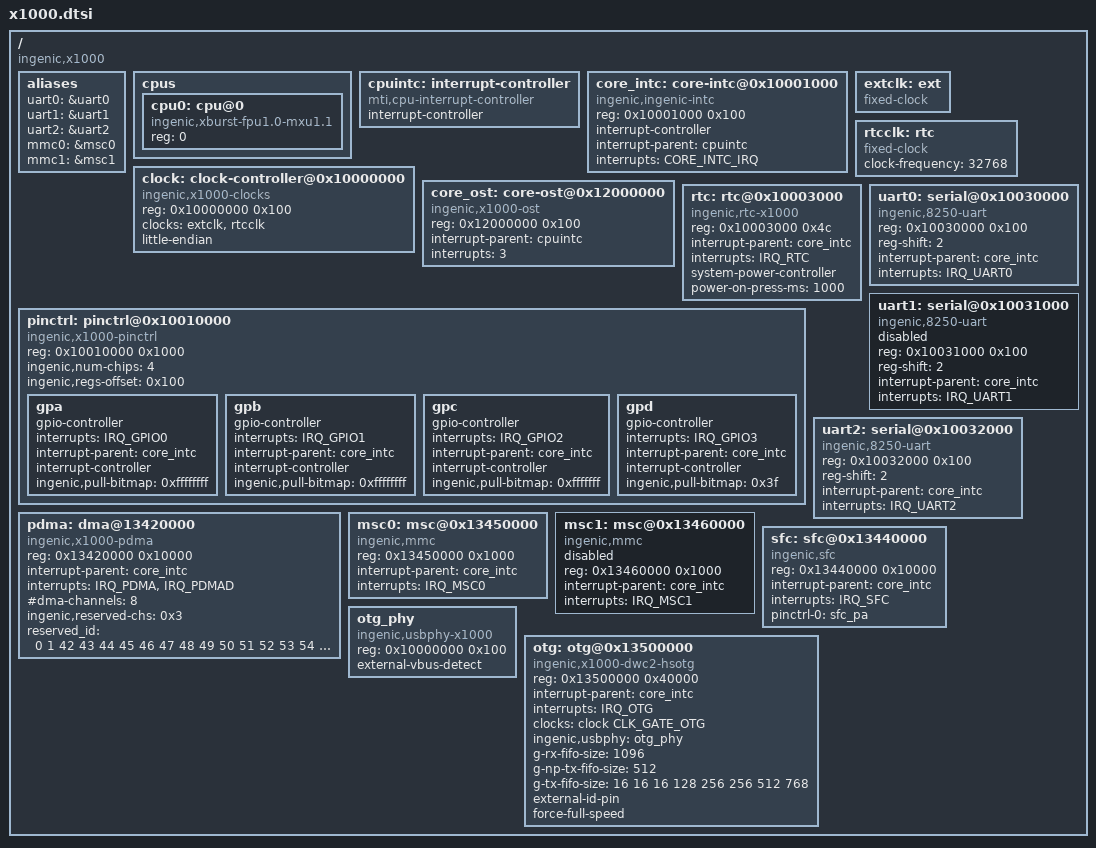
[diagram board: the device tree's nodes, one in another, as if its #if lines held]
// SPDX-License-Identifier: GPL-2.0
#include <dt-bindings/interrupt-controller/x1000-irq.h>
#include <dt-bindings/clock/ingenic,tcu.h>
#include <dt-bindings/clock/x1000-cgu.h>
#include <dt-bindings/clock/ingenic-x1000.h>
#include <dt-bindings/dma/x1000-dma.h>

/ {
	#address-cells = <1>;
	#size-cells = <1>;
	compatible = "ingenic,x1000", "ingenic,x1000e";

	aliases: aliases {
		uart0 = &uart0;
		uart1 = &uart1;
		uart2 = &uart2;
		mmc0 = &msc0;
		mmc1 = &msc1;
	};

	cpus {
		#address-cells = <1>;
		#size-cells = <0>;

		cpu0: cpu@0 {
			device_type = "cpu";
			compatible = "ingenic,xburst-fpu1.0-mxu1.1";
			reg = <0>;

			clock-names = "cpu";
		};
	};

	cpuintc: interrupt-controller {
		#address-cells = <0>;
		#interrupt-cells = <1>;
		interrupt-controller;
		compatible = "mti,cpu-interrupt-controller";
	};

	core_intc: core-intc@0x10001000 {
		compatible = "ingenic,ingenic-intc";
		reg = <0x10001000 0x100>;
		interrupt-controller;
		#interrupt-cells = <1>;
		interrupt-parent = <&cpuintc>;
		interrupts = <CORE_INTC_IRQ>;
		interrupt-names ="intc";
	};

	extclk: ext {
		compatible = "fixed-clock";
		#clock-cells = <0>;
	};

	rtcclk: rtc {
		compatible = "fixed-clock";
		#clock-cells = <0>;
		clock-frequency = <32768>;
	};

	clock: clock-controller@0x10000000 {
		compatible = "ingenic,x1000-clocks", "syscon";
		reg = <0x10000000 0x100>;
		clocks = <&extclk>, <&rtcclk>;
		clock-names = "ext", "rtc_ext";
		#clock-cells = <1>;
		little-endian;
	};


	core_ost: core-ost@0x12000000 {
		compatible = "ingenic,x1000-ost";
		reg = <0x12000000 0x100>;
		interrupt-parent = <&cpuintc>;
		interrupt-names = "sys_ost";
		interrupts = <3>;
	};

	rtc: rtc@0x10003000 {
		compatible = "ingenic,rtc-x1000";
		reg = <0x10003000 0x4c>;
		interrupt-parent = <&core_intc>;
		interrupts = <IRQ_RTC>;
		system-power-controller;
		power-on-press-ms = <1000>;
	};


	pinctrl: pinctrl@0x10010000 {
		compatible = "ingenic,x1000-pinctrl";
		reg = <0x10010000 0x1000>;
		ingenic,num-chips = <4>;
		ingenic,regs-offset = <0x100>;

		gpa: gpa {
			gpio-controller;
			#gpio-cells = <3>;
			#ingenic,pincfg-cells = <3>;
			#ingenic,pinmux-cells = <2>;
			interrupts = <IRQ_GPIO0>;
			interrupt-parent = <&core_intc>;
			interrupt-controller;
			#interrupt-cells = <3>;
			ingenic,pull-bitmap = <0xffffffff>;
		};

		gpb: gpb {
			gpio-controller;
			#gpio-cells = <3>;
			#ingenic,pincfg-cells = <3>;
			#ingenic,pinmux-cells = <2>;
			interrupts = <IRQ_GPIO1>;
			interrupt-parent = <&core_intc>;
			interrupt-controller;
			#interrupt-cells = <3>;
			ingenic,pull-bitmap = <0xffffffff>;
		};

		gpc: gpc {
			gpio-controller;
			#gpio-cells = <3>;
			#ingenic,pincfg-cells = <3>;
			#ingenic,pinmux-cells = <2>;
			interrupts = <IRQ_GPIO2>;
			interrupt-parent = <&core_intc>;
			interrupt-controller;
			#interrupt-cells = <3>;
			ingenic,pull-bitmap = <0xfffffff>;
		};

		gpd: gpd {
			gpio-controller;
			#gpio-cells = <3>;
			#ingenic,pincfg-cells = <3>;
			#ingenic,pinmux-cells = <2>;
			interrupts = <IRQ_GPIO3>;
			interrupt-parent = <&core_intc>;
			interrupt-controller;
			#interrupt-cells = <3>;
			ingenic,pull-bitmap = <0x3f>;
		};
	};

	uart0: serial@0x10030000 {
		compatible = "ingenic,8250-uart";
		reg = <0x10030000 0x100>;
		reg-shift = <2>;
		interrupt-parent = <&core_intc>;
		interrupts = <IRQ_UART0>;
		status = "okay";
		#address-cells = <1>;
		#size-cells = <0>;
	};

	uart1: serial@0x10031000 {
		compatible = "ingenic,8250-uart";
		reg = <0x10031000 0x100>;
		reg-shift = <2>;
		interrupt-parent = <&core_intc>;
		interrupts = <IRQ_UART1>;
		status = "disabled";
		#address-cells = <1>;
		#size-cells = <0>;
	};

	uart2: serial@0x10032000 {
		compatible = "ingenic,8250-uart";
		reg = <0x10032000 0x100>;
		reg-shift = <2>;
		interrupt-parent = <&core_intc>;
		interrupts = <IRQ_UART2>;
		status = "okay";
		#address-cells = <1>;
		#size-cells = <0>;
	};

	pdma: dma@13420000 {
		compatible = "ingenic,x1000-pdma";
		reg = <0x13420000 0x10000>;
		interrupt-parent = <&core_intc>;
		interrupt-names = "pdma", "pdmad";
		interrupts = <IRQ_PDMA>, <IRQ_PDMAD>;
		#dma-channels = <8>;
		#dma-cells = <1>;
		ingenic,reserved-chs = <0x3>;
		reserved_id = <0 1 42 43 44 45 46 47 48 49 50 51 52 53 54 55 56 57 58 59 60 61 62 63>;
	};

	msc0: msc@0x13450000 {
		compatible = "ingenic,mmc";
		reg = <0x13450000 0x1000>;
		interrupt-parent = <&core_intc>;
		interrupts = <IRQ_MSC0>;
	};

	msc1: msc@0x13460000 {
		compatible = "ingenic,mmc";
		reg = <0x13460000 0x1000>;
		status = "disabled";
		interrupt-parent = <&core_intc>;
		interrupts = <IRQ_MSC1>;
	};

	sfc: sfc@0x13440000 {
		compatible = "ingenic,sfc";
		reg = <0x13440000 0x10000>;
		interrupt-parent = <&core_intc>;
		interrupts = <IRQ_SFC>;
		pinctrl-names = "default";
		pinctrl-0 = <&sfc_pa>;
	};

	otg_phy: otg_phy {
		#address-cells = <1>;
		#size-cells = <1>;
		compatible = "ingenic,usbphy-x1000";
		reg = <0x10000000 0x100>;
		#phy-cells = <0>;
#ifdef CONFIG_USB_DWC2_EXT_VBUS_DETECT
		external-vbus-detect;
#endif
	};

	otg: otg@0x13500000 {
	compatible = "ingenic,x1000-dwc2-hsotg";
	reg = <0x13500000 0x40000>;
	interrupt-parent = <&core_intc>;
	interrupts = <IRQ_OTG>;
	clocks = <&clock CLK_GATE_OTG>;
	clock-names = "gate_otg";
	ingenic,usbphy = <&otg_phy>;

	g-rx-fifo-size = <1096>;
	g-np-tx-fifo-size = <512>;
	g-tx-fifo-size = <16 16 16 128 256 256 512 768>;
	status = "okay";
#ifdef CONFIG_USB_DWC2_EXT_ID_PIN
	external-id-pin;
#endif
#ifdef CONFIG_USB_DWC2_FORCE_FULL_SPEED
	force-full-speed;
#endif
	};
};

#include "x1000-pinctrl.dtsi"
